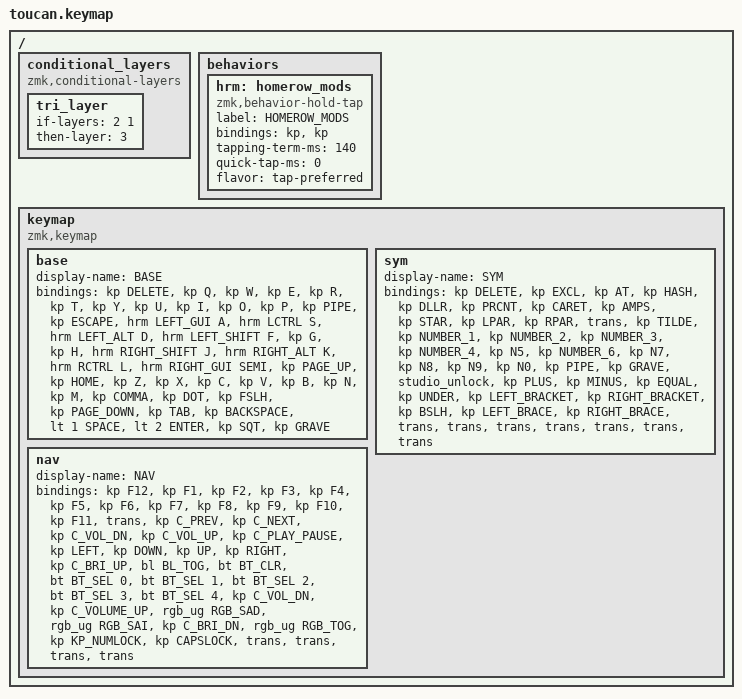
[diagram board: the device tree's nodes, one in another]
#include <behaviors.dtsi>
#include <dt-bindings/zmk/backlight.h>
#include <dt-bindings/zmk/bt.h>
#include <dt-bindings/zmk/keys.h>
#include <dt-bindings/zmk/rgb.h>

#define BASE 0
#define NAV  1
#define SYM  2
#define ADJ  3

/ {
    conditional_layers {
        compatible = "zmk,conditional-layers";

        tri_layer {
            if-layers = <2 1>;
            then-layer = <3>;
        };
    };

    behaviors {
        hrm: homerow_mods {
            compatible = "zmk,behavior-hold-tap";
            label = "HOMEROW_MODS";
            bindings = <&kp>, <&kp>;

            #binding-cells = <2>;
            tapping-term-ms = <140>;
            quick-tap-ms = <0>;
            flavor = "tap-preferred";
        };
    };

    keymap {
        compatible = "zmk,keymap";

        base {
            display-name = "BASE";
            bindings = <
&kp DELETE  &kp Q  &kp W  &kp E  &kp R  &kp T  &kp Y  &kp U  &kp I  &kp O  &kp P  &kp PIPE  &kp ESCAPE  &hrm LEFT_GUI A  &hrm LCTRL S  &hrm LEFT_ALT D  &hrm LEFT_SHIFT F  &kp G  &kp H  &hrm RIGHT_SHIFT J  &hrm RIGHT_ALT K  &hrm RCTRL L  &hrm RIGHT_GUI SEMI  &kp PAGE_UP  &kp HOME  &kp Z  &kp X  &kp C  &kp V  &kp B  &kp N  &kp M  &kp COMMA  &kp DOT  &kp FSLH  &kp PAGE_DOWN  &kp TAB  &kp BACKSPACE  &lt 1 SPACE  &lt 2 ENTER  &kp SQT  &kp GRAVE
            >;
        };

        sym {
            display-name = "SYM";
            bindings = <
&kp DELETE  &kp EXCL  &kp AT  &kp HASH  &kp DLLR  &kp PRCNT  &kp CARET  &kp AMPS  &kp STAR  &kp LPAR  &kp RPAR  &trans  &kp TILDE  &kp NUMBER_1  &kp NUMBER_2  &kp NUMBER_3  &kp NUMBER_4  &kp N5  &kp NUMBER_6  &kp N7  &kp N8  &kp N9  &kp N0  &kp PIPE  &kp GRAVE  &studio_unlock  &kp PLUS  &kp MINUS  &kp EQUAL  &kp UNDER  &kp LEFT_BRACKET  &kp RIGHT_BRACKET  &kp BSLH  &kp LEFT_BRACE  &kp RIGHT_BRACE  &trans  &trans  &trans  &trans  &trans  &trans  &trans
            >;
        };

        nav {
            display-name = "NAV";
            bindings = <
&kp F12  &kp F1  &kp F2  &kp F3  &kp F4  &kp F5  &kp F6  &kp F7  &kp F8  &kp F9  &kp F10  &kp F11  &trans  &kp C_PREV  &kp C_NEXT  &kp C_VOL_DN  &kp C_VOL_UP  &kp C_PLAY_PAUSE  &kp LEFT  &kp DOWN  &kp UP  &kp RIGHT  &kp C_BRI_UP  &bl BL_TOG  &bt BT_CLR  &bt BT_SEL 0  &bt BT_SEL 1  &bt BT_SEL 2  &bt BT_SEL 3  &bt BT_SEL 4  &kp C_VOL_DN  &kp C_VOLUME_UP  &rgb_ug RGB_SAD  &rgb_ug RGB_SAI  &kp C_BRI_DN  &rgb_ug RGB_TOG  &kp KP_NUMLOCK  &kp CAPSLOCK  &trans  &trans  &trans  &trans
            >;
        };
    };
};
